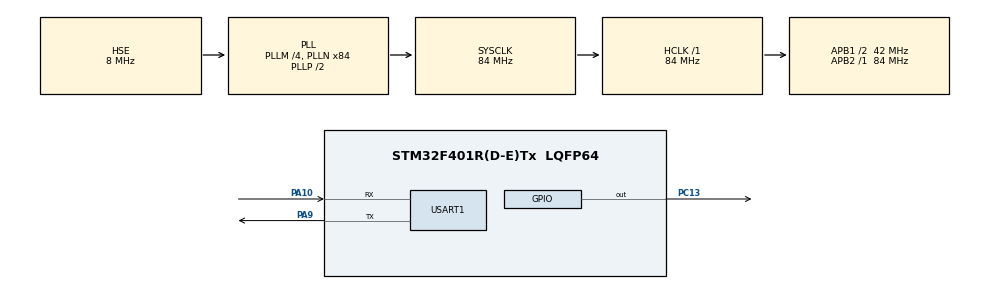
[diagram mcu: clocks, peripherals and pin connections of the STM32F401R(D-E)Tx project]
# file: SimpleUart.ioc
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Mcu.Family=STM32F4
Mcu.Name=STM32F401R(D-E)Tx
Mcu.Package=LQFP64
NVIC.PriorityGroup=NVIC_PRIORITYGROUP_4
NVIC.TIM1_UP_TIM10_IRQn=true\:0\:0\:false\:false\:true\:true\:true\:true
NVIC.USART1_IRQn=true\:0\:0\:false\:false\:true\:true\:true\:true
PA10.Mode=Asynchronous
PA10.Signal=USART1_RX
PA9.Mode=Asynchronous
PA9.Signal=USART1_TX
PC13-ANTI_TAMP.Signal=GPIO_Output
PH0\ -\ OSC_IN.Mode=HSE-External-Oscillator
PH0\ -\ OSC_IN.Signal=RCC_OSC_IN
PH1\ -\ OSC_OUT.Mode=HSE-External-Oscillator
PH1\ -\ OSC_OUT.Signal=RCC_OSC_OUT
ProjectManager.HeapSize=0x200
ProjectManager.StackSize=0x400
ProjectManager.TargetToolchain=MDK-ARM V5.32
RCC.48MHZClocksFreq_Value=42000000
RCC.AHBFreq_Value=84000000
RCC.APB1CLKDivider=RCC_HCLK_DIV2
RCC.APB1Freq_Value=42000000
RCC.APB1TimFreq_Value=84000000
RCC.APB2Freq_Value=84000000
RCC.APB2TimFreq_Value=84000000
RCC.CortexFreq_Value=84000000
RCC.HCLKFreq_Value=84000000
RCC.HSE_VALUE=8000000
RCC.HSI_VALUE=16000000
RCC.LSE_VALUE=32768
RCC.PLLM=4
RCC.PLLN=84
RCC.PLLSourceVirtual=RCC_PLLSOURCE_HSE
RCC.SYSCLKFreq_VALUE=84000000
RCC.SYSCLKSource=RCC_SYSCLKSOURCE_PLLCLK
RCC.VCOOutputFreq_Value=168000000
TIM10.AutoReloadPreload=TIM_AUTORELOAD_PRELOAD_ENABLE
TIM10.Period=1000 - 1
TIM10.Prescaler=84  - 1
USART1.VirtualMode=VM_ASYNC
VP_TIM10_VS_ClockSourceINT.Mode=Enable_Timer
board=custom

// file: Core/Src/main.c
/* USER CODE BEGIN Header */
/**
  ******************************************************************************
  * @file           : main.c
  * @brief          : Main program body
  ******************************************************************************
  * @attention
  *
  * Copyright (c) 2026 STMicroelectronics.
  * All rights reserved.
  *
  * This software is licensed under terms that can be found in the LICENSE file
  * in the root directory of this software component.
  * If no LICENSE file comes with this software, it is provided AS-IS.
  *
  ******************************************************************************
  */
/* USER CODE END Header */
#include "main.h"
#include "tim.h"
#include "usart.h"
#include "gpio.h"

/* USER CODE BEGIN Includes */
#include "zho_os.h"
#include "zho_uart.h"
#include "zho_timer_pool.h"

#include "led.h"
#include "user_app.h"
/* USER CODE END Includes */

void SystemClock_Config(void);

int main(void)
{

  /* MCU Configuration--------------------------------------------------------*/

  /* Reset of all peripherals, Initializes the Flash interface and the Systick. */
  HAL_Init();

  /* Configure the system clock */
  SystemClock_Config();

  /* Initialize all configured peripherals */
  MX_GPIO_Init();
  MX_TIM10_Init();
  MX_USART1_UART_Init();
  /* USER CODE BEGIN 2 */
	init_zho_timer_pool(&htim10);
	init_zho_uart(&huart1);

	init_led(do_something);

	zho_os_loop();
  /* USER CODE END 2 */

  /* Infinite loop */
  while (1)
  {

  }
}

void SystemClock_Config(void)
{
  RCC_OscInitTypeDef RCC_OscInitStruct = {0};
  RCC_ClkInitTypeDef RCC_ClkInitStruct = {0};

  /** Configure the main internal regulator output voltage
  */
  __HAL_RCC_PWR_CLK_ENABLE();
  __HAL_PWR_VOLTAGESCALING_CONFIG(PWR_REGULATOR_VOLTAGE_SCALE2);

  /** Initializes the RCC Oscillators according to the specified parameters
  * in the RCC_OscInitTypeDef structure.
  */
  RCC_OscInitStruct.OscillatorType = RCC_OSCILLATORTYPE_HSE;
  RCC_OscInitStruct.HSEState = RCC_HSE_ON;
  RCC_OscInitStruct.PLL.PLLState = RCC_PLL_ON;
  RCC_OscInitStruct.PLL.PLLSource = RCC_PLLSOURCE_HSE;
  RCC_OscInitStruct.PLL.PLLM = 4;
  RCC_OscInitStruct.PLL.PLLN = 84;
  RCC_OscInitStruct.PLL.PLLP = RCC_PLLP_DIV2;
  RCC_OscInitStruct.PLL.PLLQ = 4;
  if (HAL_RCC_OscConfig(&RCC_OscInitStruct) != HAL_OK)
  {
    Error_Handler();
  }

  /** Initializes the CPU, AHB and APB buses clocks
  */
  RCC_ClkInitStruct.ClockType = RCC_CLOCKTYPE_HCLK|RCC_CLOCKTYPE_SYSCLK
                              |RCC_CLOCKTYPE_PCLK1|RCC_CLOCKTYPE_PCLK2;
  RCC_ClkInitStruct.SYSCLKSource = RCC_SYSCLKSOURCE_PLLCLK;
  RCC_ClkInitStruct.AHBCLKDivider = RCC_SYSCLK_DIV1;
  RCC_ClkInitStruct.APB1CLKDivider = RCC_HCLK_DIV2;
  RCC_ClkInitStruct.APB2CLKDivider = RCC_HCLK_DIV1;

  if (HAL_RCC_ClockConfig(&RCC_ClkInitStruct, FLASH_LATENCY_2) != HAL_OK)
  {
    Error_Handler();
  }
}

void Error_Handler(void)
{
  __disable_irq();
  while (1)
  {
  }
}
